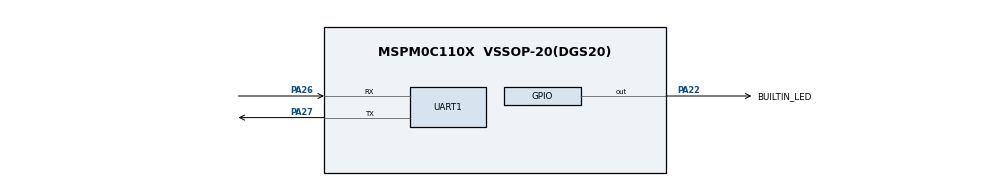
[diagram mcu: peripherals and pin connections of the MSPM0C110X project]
/**
 * @cliArgs --device "MSPM0C110X" --part "Default" --package "VSSOP-20(DGS20)" --product "mspm0_sdk@2.04.00.06"
 * @versions {"tool":"1.22.0+3893"}
 */

/**
 * Import the modules used in this configuration.
 */
const GPIO          = scripting.addModule("/ti/driverlib/GPIO", {}, false);
const GPIO1         = GPIO.addInstance();
const SYSCTL        = scripting.addModule("/ti/driverlib/SYSCTL");
const UART          = scripting.addModule("/ti/driverlib/UART", {}, false);
const UART1         = UART.addInstance();
const ProjectConfig = scripting.addModule("/ti/project_config/ProjectConfig");

/**
 * Write custom configuration values to the imported modules.
 */
GPIO1.$name                              = "GPIOA";
GPIO1.associatedPins.create(2);
GPIO1.associatedPins[0].$name            = "BUILTIN_LED";
GPIO1.associatedPins[0].assignedPort     = "PORTA";
GPIO1.associatedPins[0].initialValue     = "SET";
GPIO1.associatedPins[0].pin.$assign      = "PA22";
GPIO1.associatedPins[1].$name            = "ENTER_BLD";
GPIO1.associatedPins[1].direction        = "INPUT";
GPIO1.associatedPins[1].assignedPort     = "PORTA";
GPIO1.associatedPins[1].internalResistor = "PULL_UP";
GPIO1.associatedPins[1].ioStructure      = "SD";

const Board = scripting.addModule("/ti/driverlib/Board", {}, false);

SYSCTL.clockTreeEn = true;

UART1.$name                    = "UART_0";
UART1.enabledInterrupts        = ["RX"];
UART1.targetBaudRate           = 115200;
UART1.peripheral.rxPin.$assign = "PA26";
UART1.peripheral.txPin.$assign = "PA27";
UART1.txPinConfig.$name        = "ti_driverlib_gpio_GPIOPinGeneric0";
UART1.rxPinConfig.$name        = "ti_driverlib_gpio_GPIOPinGeneric1";

ProjectConfig.genStartup = false;
ProjectConfig.genLinker  = false;

/**
 * Pinmux solution for unlocked pins/peripherals. This ensures that minor changes to the automatic solver in a future
 * version of the tool will not impact the pinmux you originally saw.  These lines can be completely deleted in order to
 * re-solve from scratch.
 */
GPIO1.associatedPins[1].pin.$suggestSolution = "PA28";
Board.peripheral.$suggestSolution            = "DEBUGSS";
Board.peripheral.swclkPin.$suggestSolution   = "PA20";
Board.peripheral.swdioPin.$suggestSolution   = "PA19";
UART1.peripheral.$suggestSolution            = "UART0";
